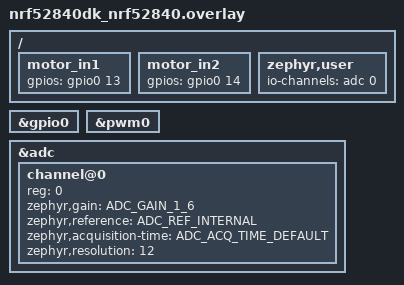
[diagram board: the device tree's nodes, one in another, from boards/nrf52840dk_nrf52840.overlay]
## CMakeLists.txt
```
# BLE Switch: Zephyr application (pure C application logic)
cmake_minimum_required(VERSION 3.20.0)
find_package(Zephyr REQUIRED HINTS $ENV{ZEPHYR_BASE})
project(ble_switch)

# Application sources (C)
target_sources(app PRIVATE
  src/main.c
  src/ble/ble_service.c
  src/motor/motor_driver.c
  src/motor/motor_fsm.c
  src/UI/button.c
  src/UI/led.c
  src/power/battery.c
  src/power/sleep.c
  src/storage/nvs_storage.c
)
target_include_directories(app PRIVATE
  ${CMAKE_CURRENT_SOURCE_DIR}/src
  ${CMAKE_CURRENT_SOURCE_DIR}/src/ble
  ${CMAKE_CURRENT_SOURCE_DIR}/src/motor
  ${CMAKE_CURRENT_SOURCE_DIR}/src/power
  ${CMAKE_CURRENT_SOURCE_DIR}/src/UI
  ${CMAKE_CURRENT_SOURCE_DIR}/src/storage
  ${CMAKE_CURRENT_SOURCE_DIR}/include
)
```

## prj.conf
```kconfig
# BLE Switch: BLE peripheral + GPIO/PWM (nRF5340 DK app core + net core HCI RPMsg)
CONFIG_BT=y
CONFIG_BT_PERIPHERAL=y
CONFIG_BT_DEVICE_NAME="BLE Switch"
CONFIG_BT_MAX_CONN=1
CONFIG_BT_MAX_PAIRED=1
CONFIG_BT_SMP=y
CONFIG_BT_APP_PASSKEY=y
CONFIG_BT_SETTINGS=y
CONFIG_SETTINGS=y

# Match Host ACL TX buffers to Controller's ACL packets
CONFIG_BT_BUF_ACL_TX_COUNT=7

CONFIG_GPIO=y
CONFIG_PWM=y
CONFIG_ADC=y
CONFIG_FLASH=y
CONFIG_FLASH_MAP=y
CONFIG_NVS=y

CONFIG_MAIN_STACK_SIZE=2048
CONFIG_SYSTEM_WORKQUEUE_STACK_SIZE=2048

CONFIG_LOG=y
CONFIG_LOG_DEFAULT_LEVEL=3
```

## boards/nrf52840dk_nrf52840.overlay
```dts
/*
 * nRF52840 DK overlay
 *
 * Enable GPIO/PWM and define simple GPIO-based motor control pins.
 * The actual H-bridge / driver hardware should connect to these pins.
 */

&gpio0 {
	status = "okay";
};

/*
 * Two GPIOs used for motor direction:
 * - motor_in1: drives \"ON\" direction
 * - motor_in2: drives \"OFF\" direction
 *
 * These can be wired to an H-bridge or driver inputs.
 */
/ {
	motor_in1: motor_in1 {
		gpios = <&gpio0 13 GPIO_ACTIVE_HIGH>;
	};

	motor_in2: motor_in2 {
		gpios = <&gpio0 14 GPIO_ACTIVE_HIGH>;
	};
};

&pwm0 {
	status = "okay";
};

/* ADC configuration for battery measurement.
 * We re-use the pattern from Zephyr's adc_dt sample and expose one
 * ADC channel via zephyr,user io-channels. For nRF52840 DK this maps
 * to AIN0 (P0.03) by default.
 */
/ {
	zephyr,user {
		io-channels = <&adc 0>;
	};
};

&adc {
	#address-cells = <1>;
	#size-cells = <0>;

	channel@0 {
		reg = <0>;
		zephyr,gain = "ADC_GAIN_1_6";
		zephyr,reference = "ADC_REF_INTERNAL";
		zephyr,acquisition-time = <ADC_ACQ_TIME_DEFAULT>;
		/* input-positive left as board default for AIN0 (P0.03) */
		zephyr,resolution = <12>;
	};
};
```

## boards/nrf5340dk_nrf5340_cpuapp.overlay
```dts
/*
 * nRF5340 DK (application core) overlay
 *
 * Enable GPIO/ADC and define simple GPIO-based motor control pins.
 * The actual H-bridge / driver hardware should connect to these pins.
 */

&gpio0 {
	status = "okay";
};

/*
 * Two GPIOs used for motor direction:
 * - motor_in1: drives "ON" direction
 * - motor_in2: drives "OFF" direction
 *
 * These can be wired to an H-bridge or driver inputs.
 */
/ {
	motor_in1: motor_in1 {
		gpios = <&gpio0 13 GPIO_ACTIVE_HIGH>;
	};

	motor_in2: motor_in2 {
		gpios = <&gpio0 14 GPIO_ACTIVE_HIGH>;
	};
};

/* ADC configuration for battery measurement.
 * We expose one ADC channel via zephyr,user io-channels; the exact analog pin
 * is defined by the board's ADC channel 0 default.
 */
/ {
	zephyr,user {
		io-channels = <&adc 0>;
	};
};

&adc {
	#address-cells = <1>;
	#size-cells = <0>;

	channel@0 {
		reg = <0>;
		zephyr,gain = "ADC_GAIN_1_6";
		zephyr,reference = "ADC_REF_INTERNAL";
		zephyr,acquisition-time = <ADC_ACQ_TIME_DEFAULT>;
		zephyr,resolution = <12>;
	};
};
```

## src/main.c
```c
/*
 * BLE Switch - main entry
 * Initializes app logic, BLE, button, storage trigger; then idle.
 */
#include "ble_service.h"
#include "button.h"
#include "nvs_storage.h"
#include "led.h"
#include <zephyr/init.h>
#include <zephyr/kernel.h>

extern void app_init(void);

static int ble_switch_init(void)
{
	app_init();
	return 0;
}

SYS_INIT(ble_switch_init, APPLICATION, CONFIG_APPLICATION_INIT_PRIORITY);

int main(void)
{
	led_init();
	ble_svc_init();
	button_init();
	nvs_storage_save_trigger_init();
	k_sleep(K_FOREVER);

	return 0;
}
```

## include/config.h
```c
#ifndef CONFIG_H
#define CONFIG_H

/* Global configuration parameters for the BLE switch application.
 * This is a placeholder and can be extended with user-tunable settings.
 */

#endif /* CONFIG_H */
```

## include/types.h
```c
#ifndef TYPES_H
#define TYPES_H

/* Common type definitions placeholder. The project currently uses only
 * standard integer types from <stdint.h>.
 */

#endif /* TYPES_H */
```

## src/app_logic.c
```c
#include <stdbool.h>
#include <stdint.h>
#include <zephyr/kernel.h>
#include <zephyr/logging/log.h>

LOG_MODULE_REGISTER(app_logic, LOG_LEVEL_INF);

#include "hw_glue.h"
#include "timer_glue.h"

/* Application state and logic previously implemented in Rust,
 * now reimplemented in pure C.
 */

typedef enum {
	STATE_IDLE = 0,
	STATE_MOVING_TO_ON = 1,
	STATE_MOVING_TO_OFF = 2,
	STATE_ERROR = 3,
} machine_state_t;

struct app_state {
	machine_state_t machine_state;
	uint8_t physical_state; /* 0 = off position, 1 = on position */
	uint8_t orientation;    /* 0 = normal, 1 = inverted */
	bool pairing_mode;
};

static struct app_state g_state;

static uint8_t app_get_battery_level(void)
{
	return battery_read_percent();
}

static bool app_is_battery_too_low_for_motion(void)
{
	return app_get_battery_level() <= 10;
}

static uint8_t app_get_logical_state(void)
{
	uint8_t p = g_state.physical_state & 1U;
	uint8_t o = g_state.orientation & 1U;
	if (o == 0U) {
		return p;
	}
	return (uint8_t)(1U - p);
}

static void app_request_on(void);
static void app_request_off(void);

static void app_request_toggle(void)
{
	uint8_t logical = app_get_logical_state();
	if (logical != 0U) {
		app_request_off();
	} else {
		app_request_on();
	}
}

#define MOTION_TIMEOUT_MS 1500U

static void app_request_on(void)
{
	if (g_state.machine_state != STATE_IDLE) {
		LOG_DBG("request_on ignored, state=%d", g_state.machine_state);
		return;
	}
	if (app_is_battery_too_low_for_motion()) {
		LOG_WRN("Battery too low, cannot move to ON (level=%u%%)", app_get_battery_level());
		g_state.machine_state = STATE_ERROR;
		led_flash_error();
		return;
	}
	LOG_INF("Moving to ON (orientation=%u, physical=%u)", g_state.orientation, g_state.physical_state);
	g_state.machine_state = STATE_MOVING_TO_ON;
	motor_power_enable(true);
	motor_move_to_on();
	timer_glue_start_motion_timeout_ms(MOTION_TIMEOUT_MS);
}

static void app_request_off(void)
{
	if (g_state.machine_state != STATE_IDLE) {
		LOG_DBG("request_off ignored, state=%d", g_state.machine_state);
		return;
	}
	if (app_is_battery_too_low_for_motion()) {
		LOG_WRN("Battery too low, cannot move to OFF (level=%u%%)", app_get_battery_level());
		g_state.machine_state = STATE_ERROR;
		led_flash_error();
		return;
	}
	LOG_INF("Moving to OFF (orientation=%u, physical=%u)", g_state.orientation, g_state.physical_state);
	g_state.machine_state = STATE_MOVING_TO_OFF;
	motor_power_enable(true);
	motor_move_to_off();
	timer_glue_start_motion_timeout_ms(MOTION_TIMEOUT_MS);
}

/* -------- Public API: application logic entry points -------- */

/* Called from SYS_INIT hook in main.c. */
void app_init(void)
{
	uint8_t v;

	g_state.machine_state = STATE_IDLE;
	g_state.physical_state = 0U;
	g_state.orientation = 0U;
	g_state.pairing_mode = false;

	if (storage_read_physical(&v) == 0) {
		g_state.physical_state = v & 1U;
	}
	if (storage_read_orientation(&v) == 0) {
		g_state.orientation = v & 1U;
	}
	LOG_INF("App init: physical=%u, orientation=%u", g_state.physical_state, g_state.orientation);
}

void app_handle_switch_control(uint8_t value)
{
	LOG_INF("Switch control write: value=%u (0=off,1=on,2=toggle)", value);
	switch (value) {
	case 0: /* logical off */
		if (g_state.orientation == 0U) {
			app_request_off();
		} else {
			app_request_on();
		}
		break;
	case 1: /* logical on */
		if (g_state.orientation == 0U) {
			app_request_on();
		} else {
			app_request_off();
		}
		break;
	case 2: /* toggle */
		app_request_toggle();
		break;
	default:
		break;
	}
}

uint8_t app_get_switch_state(void)
{
	uint8_t logical = app_get_logical_state();
	LOG_DBG("Get switch state: logical=%u (physical=%u, orientation=%u)",
		logical, g_state.physical_state, g_state.orientation);
	return app_get_logical_state();
}

uint8_t app_get_orientation(void)
{
	return g_state.orientation & 1U;
}

void app_set_orientation(uint8_t value)
{
	uint8_t v = value & 1U;
	g_state.orientation = v;
	(void)storage_write_orientation(v);
	LOG_INF("Set orientation: %u", v);
}

uint8_t app_get_battery_level_api(void)
{
	uint8_t lvl = app_get_battery_level();
	LOG_DBG("Battery level: %u%%", lvl);
	return lvl;
}

uint8_t app_get_error_state(void)
{
	return (uint8_t)g_state.machine_state;
}

void app_on_button_short(void)
{
	LOG_INF("Button short press -> toggle");
	app_request_toggle();
}

void app_on_button_long(void)
{
	g_state.pairing_mode = true;
	LOG_INF("Button long press -> pairing/factory reset");
	led_flash_pairing();
	hw_factory_reset();
}

void app_on_motion_complete(void)
{
	LOG_INF("Motion complete, state before=%d", g_state.machine_state);
	timer_glue_stop_motion_timeout();
	motor_stop();
	motor_power_enable(false);

	switch (g_state.machine_state) {
	case STATE_MOVING_TO_ON:
		g_state.physical_state = 1U;
		led_flash_feedback();
		LOG_INF("Reached ON position, physical_state=%u", g_state.physical_state);
		break;
	case STATE_MOVING_TO_OFF:
		g_state.physical_state = 0U;
		led_flash_feedback();
		LOG_INF("Reached OFF position, physical_state=%u", g_state.physical_state);
		break;
	default:
		break;
	}

	g_state.machine_state = STATE_IDLE;
}

void app_clear_error(void)
{
	LOG_INF("Clear error, state from=%d to IDLE", g_state.machine_state);
	g_state.machine_state = STATE_IDLE;
}

/* Called from save-state GPIO work handler in hw_glue.c. */
void app_save_physical_state_to_nvs(void)
{
	uint8_t v = g_state.physical_state & 1U;
	int rc = storage_write_physical(v);
	if (rc == 0) {
		LOG_INF("Saved physical_state=%u to NVS", v);
	} else {
		LOG_WRN("Failed to save physical_state=%u to NVS, rc=%d", v, rc);
	}
}
```

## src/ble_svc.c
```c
/*
 * BLE GATT: Remote Mechanical Switch Service
 * - Switch Control: read/write, 1 byte 0=off, 1=on, 2=toggle
 */
#include "ble_svc.h"
#include <zephyr/kernel.h>
#include <zephyr/logging/log.h>
#include <zephyr/bluetooth/bluetooth.h>
#include <zephyr/bluetooth/conn.h>
#include <zephyr/bluetooth/gatt.h>
#include <zephyr/bluetooth/uuid.h>
#include <zephyr/settings/settings.h>
#include <zephyr/bluetooth/services/bas.h>

LOG_MODULE_REGISTER(ble_svc, LOG_LEVEL_INF);

/* Application logic API */
extern uint8_t app_get_switch_state(void);
extern void app_handle_switch_control(uint8_t value);
extern uint8_t app_get_orientation(void);
extern void app_set_orientation(uint8_t value);
extern uint8_t app_get_battery_level_api(void);
extern uint8_t app_get_error_state(void);

/* Remote Mechanical Switch Service: 0x0001-... (custom 128-bit) */
#define BT_UUID_REMOTE_SWITCH_SVC_VAL \
	BT_UUID_128_ENCODE(0x00010000, 0x1234, 0x5678, 0x1234, 0x56789abcdef0)
/* Switch Control characteristic */
#define BT_UUID_SWITCH_CTRL_VAL \
	BT_UUID_128_ENCODE(0x00010000, 0x1234, 0x5678, 0x1234, 0x56789abcdef1)
/* Installation orientation: 0 = normal, 1 = inverted (read/write, persisted in NVS) */
#define BT_UUID_ORIENTATION_VAL \
	BT_UUID_128_ENCODE(0x00010000, 0x1234, 0x5678, 0x1234, 0x56789abcdef2)

static const struct bt_uuid_128 remote_switch_svc_uuid = BT_UUID_INIT_128(
	BT_UUID_REMOTE_SWITCH_SVC_VAL);
static const struct bt_uuid_128 switch_ctrl_uuid = BT_UUID_INIT_128(
	BT_UUID_SWITCH_CTRL_VAL);
static const struct bt_uuid_128 orientation_uuid = BT_UUID_INIT_128(
	BT_UUID_ORIENTATION_VAL);

/* Battery Level Service (BAS), 0x180F, with a single read-only Battery Level characteristic. */
static ssize_t read_batt_level(struct bt_conn *conn,
			       const struct bt_gatt_attr *attr,
			       void *buf, uint16_t len, uint16_t offset)
{
	uint8_t lvl = app_get_battery_level_api();
	return bt_gatt_attr_read(conn, attr, buf, len, offset, &lvl, sizeof(lvl));
}

BT_GATT_SERVICE_DEFINE(bas_svc,
	BT_GATT_PRIMARY_SERVICE(BT_UUID_BAS),
	BT_GATT_CHARACTERISTIC(BT_UUID_BAS_BATTERY_LEVEL,
			       BT_GATT_CHRC_READ,
			       BT_GATT_PERM_READ,
			       read_batt_level, NULL, NULL),
);

/* Application-provided fixed passkey.
 * For now this is hard-coded; in future it can be loaded from NVS or provided by MCUboot.
 */
#if defined(CONFIG_BT_APP_PASSKEY)
static uint32_t app_fixed_passkey = 123456;

static uint32_t auth_app_passkey(struct bt_conn *conn)
{
	ARG_UNUSED(conn);
	return app_fixed_passkey;
}

static const struct bt_conn_auth_cb auth_cb = {
	.app_passkey = auth_app_passkey,
};
#endif

/* Simple error/status characteristic: exposes the current state/error code from Rust.
 * 0 = Idle/OK, 1 = MovingToOn, 2 = MovingToOff, 3 = Error.
 */
static ssize_t read_error_state(struct bt_conn *conn,
				const struct bt_gatt_attr *attr,
				void *buf, uint16_t len, uint16_t offset)
{
	uint8_t val = app_get_error_state();
	return bt_gatt_attr_read(conn, attr, buf, len, offset, &val, sizeof(val));
}

BT_GATT_SERVICE_DEFINE(status_svc,
	BT_GATT_PRIMARY_SERVICE(BT_UUID_DECLARE_16(0x180A)), /* reuse Device Info UUID namespace */
	BT_GATT_CHARACTERISTIC(BT_UUID_DECLARE_16(0x2A3D), /* arbitrary 16-bit for status */
			       BT_GATT_CHRC_READ,
			       BT_GATT_PERM_READ,
			       read_error_state, NULL, NULL),
);

static ssize_t read_switch_ctrl(struct bt_conn *conn,
				const struct bt_gatt_attr *attr,
				void *buf, uint16_t len, uint16_t offset)
{
	uint8_t val = app_get_switch_state();
	return bt_gatt_attr_read(conn, attr, buf, len, offset, &val, sizeof(val));
}

static ssize_t write_switch_ctrl(struct bt_conn *conn,
				 const struct bt_gatt_attr *attr,
				 const void *buf, uint16_t len, uint16_t offset,
				 uint8_t flags)
{
	if (offset != 0 || len != 1) {
		return BT_GATT_ERR(BT_ATT_ERR_INVALID_OFFSET);
	}

	uint8_t val = *(const uint8_t *)buf;
	switch (val) {
		case 0:
		case 1:
		case 2:
			break;
		default:
			return BT_GATT_ERR(BT_ATT_ERR_VALUE_NOT_ALLOWED);
	}

	app_handle_switch_control(val);
	return len;
}

static ssize_t read_orientation(struct bt_conn *conn,
				const struct bt_gatt_attr *attr,
				void *buf, uint16_t len, uint16_t offset)
{
	uint8_t val = app_get_orientation();
	LOG_DBG("GATT Orientation read: %u", val);
	return bt_gatt_attr_read(conn, attr, buf, len, offset, &val, sizeof(val));
}

static ssize_t write_orientation(struct bt_conn *conn,
				  const struct bt_gatt_attr *attr,
				  const void *buf, uint16_t len, uint16_t offset,
				  uint8_t flags)
{
	if (offset != 0 || len != 1) {
		return BT_GATT_ERR(BT_ATT_ERR_INVALID_OFFSET);
	}

	uint8_t val = *(const uint8_t *)buf;
	switch (val) {
	case 0:
	case 1:
		break;
	default:
		return BT_GATT_ERR(BT_ATT_ERR_VALUE_NOT_ALLOWED);
	}

	LOG_INF("GATT Orientation write: %u", val);
	app_set_orientation(val);
	return len;
}

BT_GATT_SERVICE_DEFINE(remote_switch_svc,
	BT_GATT_PRIMARY_SERVICE(&remote_switch_svc_uuid),
	BT_GATT_CHARACTERISTIC(&switch_ctrl_uuid.uuid,
			       BT_GATT_CHRC_READ | BT_GATT_CHRC_WRITE,
			       BT_GATT_PERM_READ | BT_GATT_PERM_WRITE,
			       read_switch_ctrl, write_switch_ctrl, NULL),
	BT_GATT_CHARACTERISTIC(&orientation_uuid.uuid,
			       BT_GATT_CHRC_READ | BT_GATT_CHRC_WRITE,
			       BT_GATT_PERM_READ | BT_GATT_PERM_WRITE,
			       read_orientation, write_orientation, NULL),
);

static const struct bt_data ad[] = {
	BT_DATA_BYTES(BT_DATA_FLAGS, (BT_LE_AD_GENERAL | BT_LE_AD_NO_BREDR)),
	BT_DATA_BYTES(BT_DATA_UUID128_ALL, BT_UUID_REMOTE_SWITCH_SVC_VAL),
	/* Advertise standard Battery Service (0x180F) as 16-bit UUID */
	BT_DATA_BYTES(BT_DATA_UUID16_ALL, 0x0F, 0x18),
};

static const struct bt_data sd[] = {
	BT_DATA(BT_DATA_NAME_COMPLETE, CONFIG_BT_DEVICE_NAME,
		sizeof(CONFIG_BT_DEVICE_NAME) - 1),
};

static void bt_ready(int err)
{
	if (err) {
		LOG_ERR("bt_enable failed: %d", err);
		return;
	}

	if (IS_ENABLED(CONFIG_SETTINGS)) {
        settings_load();
    }

	LOG_INF("bt_enable OK, starting advertising");
	err = ble_svc_advertise_start();
	if (err) {
		LOG_ERR("Advertising start failed: %d", err);
	} else {
		LOG_INF("Advertising started successfully");
	}
}

void ble_svc_init(void)
{
	int err;

#if defined(CONFIG_BT_APP_PASSKEY)
	bt_conn_auth_cb_register(&auth_cb);
#endif

	err = bt_enable(bt_ready);
	if (err) {
		LOG_ERR("bt_enable failed: %d", err);
	}
}

int ble_svc_advertise_start(void)
{
	/* Use GAP recommended fast connectable advertising parameters */
	return bt_le_adv_start(BT_LE_ADV_CONN_FAST_1, ad, ARRAY_SIZE(ad),
			       sd, ARRAY_SIZE(sd));
}
```

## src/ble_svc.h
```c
#ifndef BLE_SVC_H
#define BLE_SVC_H

/* Initialize BLE stack and register GATT service. Call once after bt_enable. */
void ble_svc_init(void);

/* Start advertising. Call from bt_ready callback. */
int ble_svc_advertise_start(void);

#endif
```

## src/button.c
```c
#include "button.h"
#include <zephyr/kernel.h>
#include <zephyr/device.h>
#include <zephyr/drivers/gpio.h>
#include <zephyr/devicetree.h>
#include <zephyr/logging/log.h>

LOG_MODULE_REGISTER(button, LOG_LEVEL_INF);

extern void app_on_button_short(void);
extern void app_on_button_long(void);

#define LONG_PRESS_MS 2000
#define BUTTON_PRESSED_VAL 1

#if DT_NODE_EXISTS(DT_ALIAS(sw0))
#define SW0_NODE DT_ALIAS(sw0)
#else
#error "No sw0 alias (button) in devicetree"
#endif

static const struct gpio_dt_spec button = GPIO_DT_SPEC_GET(SW0_NODE, gpios);
static struct gpio_callback button_cb;
static struct k_timer long_press_timer;
static volatile bool long_press_fired;

static void long_press_expiry(struct k_timer *timer)
{
	ARG_UNUSED(timer);
	long_press_fired = true;
	LOG_INF("Button long-press timeout");
	app_on_button_long();
}

static void button_handler(const struct device *dev, struct gpio_callback *cb, uint32_t pins)
{
	ARG_UNUSED(dev);
	ARG_UNUSED(cb);
	ARG_UNUSED(pins);

	int val = gpio_pin_get_dt(&button);
	if (val == BUTTON_PRESSED_VAL) {
		/* Pressed: start long-press timer */
		LOG_DBG("Button pressed");
		long_press_fired = false;
		k_timer_start(&long_press_timer, K_MSEC(LONG_PRESS_MS), K_NO_WAIT);
	} else {
		/* Released */
		LOG_DBG("Button released");
		k_timer_stop(&long_press_timer);
		if (!long_press_fired) {
			LOG_INF("Button short press");
			app_on_button_short();
		}
	}
}

void button_init(void)
{
	if (!gpio_is_ready_dt(&button)) {
		return;
	}
	gpio_pin_configure_dt(&button, GPIO_INPUT);
	gpio_pin_interrupt_configure_dt(&button, GPIO_INT_EDGE_BOTH);
	k_timer_init(&long_press_timer, long_press_expiry, NULL);
	gpio_init_callback(&button_cb, button_handler, BIT(button.pin));
	gpio_add_callback(button.port, &button_cb);
}
```

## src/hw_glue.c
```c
#include "hw_glue.h"
#include <stdbool.h>
#include <zephyr/kernel.h>
#include <zephyr/device.h>
#include <zephyr/drivers/gpio.h>
#include <zephyr/devicetree.h>
#include <zephyr/storage/flash_map.h>
#include <zephyr/fs/nvs.h>
#include <zephyr/drivers/adc.h>
#include <zephyr/bluetooth/bluetooth.h>
#include <zephyr/logging/log.h>

LOG_MODULE_REGISTER(hw_glue, LOG_LEVEL_INF);

/* Motor: simple GPIO-based H-bridge style control using GPIO0 pins.
 * Two pins (IN1/IN2) drive ON/OFF direction.
 */

#define MOTOR_IN1_PIN 13
#define MOTOR_IN2_PIN 14

static const struct device *motor_port = DEVICE_DT_GET(DT_NODELABEL(gpio0));
static bool motor_pins_inited;

static void motor_init_pins(void)
{
	if (motor_pins_inited) {
		return;
	}
	if (!device_is_ready(motor_port)) {
		return;
	}
	gpio_pin_configure(motor_port, MOTOR_IN1_PIN, GPIO_OUTPUT_INACTIVE);
	gpio_pin_configure(motor_port, MOTOR_IN2_PIN, GPIO_OUTPUT_INACTIVE);
	motor_pins_inited = true;
}

void motor_move_to_on(void)
{
	motor_init_pins();
	if (!motor_pins_inited) {
		return;
	}
	/* Drive ON direction: IN1=1, IN2=0 */
	LOG_INF("Motor move_to_on");
	gpio_pin_set(motor_port, MOTOR_IN1_PIN, 1);
	gpio_pin_set(motor_port, MOTOR_IN2_PIN, 0);
}

void motor_move_to_off(void)
{
	motor_init_pins();
	if (!motor_pins_inited) {
		return;
	}
	/* Drive OFF direction: IN1=0, IN2=1 */
	LOG_INF("Motor move_to_off");
	gpio_pin_set(motor_port, MOTOR_IN1_PIN, 0);
	gpio_pin_set(motor_port, MOTOR_IN2_PIN, 1);
}

void motor_stop(void)
{
	motor_init_pins();
	if (!motor_pins_inited) {
		return;
	}
	/* Brake / stop: both low */
	LOG_DBG("Motor stop");
	gpio_pin_set(motor_port, MOTOR_IN1_PIN, 0);
	gpio_pin_set(motor_port, MOTOR_IN2_PIN, 0);
}

void motor_power_enable(bool enable)
{
	/* For simple two-pin control, power enable just maps to stop/idle. */
	if (!enable) {
		motor_stop();
	}
}

/* LED: short flash if led0 exists (e.g. nRF5340 DK LED1) */
#if DT_NODE_EXISTS(DT_ALIAS(led0))
static const struct gpio_dt_spec led = GPIO_DT_SPEC_GET(DT_ALIAS(led0), gpios);
static struct k_timer led_off_timer;
static bool led_timer_init_done;
static void led_off_handler(struct k_timer *t)
{
	ARG_UNUSED(t);
	gpio_pin_set_dt(&led, 0);
}
static void led_flash_ms(uint32_t ms)
{
	if (!gpio_is_ready_dt(&led)) return;
	if (!led_timer_init_done) {
		k_timer_init(&led_off_timer, led_off_handler, NULL);
		led_timer_init_done = true;
	}
	gpio_pin_configure_dt(&led, GPIO_OUTPUT_INACTIVE);
	gpio_pin_set_dt(&led, 1);
	k_timer_start(&led_off_timer, K_MSEC(ms), K_NO_WAIT);
}
#else
static void led_flash_ms(uint32_t ms) { (void)ms; }
#endif

void led_flash_pairing(void)
{
	LOG_INF("LED pairing flash");
	led_flash_ms(100);
}

void led_flash_feedback(void) { led_flash_ms(80); }
void led_flash_error(void) { led_flash_ms(200); }

/* Simple NVS-backed storage for logical switch state.
 * Uses the fixed-partition labeled 'storage' (node label storage_partition).
 */
static struct nvs_fs nvs;
static bool nvs_inited;

static int storage_nvs_init(void)
{
	int rc;
	const struct flash_area *fa;

	if (nvs_inited) {
		return 0;
	}

	rc = flash_area_open(FIXED_PARTITION_ID(storage_partition), &fa);
	if (rc) {
		return rc;
	}

	nvs.offset = fa->fa_off;
	nvs.sector_size = fa->fa_size / 2;
	nvs.sector_count = 2;
	nvs.flash_device = fa->fa_dev;

	rc = nvs_mount(&nvs);
	if (rc) {
		return rc;
	}

	nvs_inited = true;
	return 0;
}

/* NVS: physical motor position (0/1) and logical↔physical mapping (0=normal, 1=inverted).
 * Physical state is written only when save-state GPIO goes low (to limit NVS wear). */
#define NVS_ID_PHYSICAL_STATE 1
#define NVS_ID_ORIENTATION    2

int storage_read_physical(uint8_t *out_value)
{
	int rc;
	uint8_t val;

	rc = storage_nvs_init();
	if (rc) {
		if (out_value) *out_value = 0;
		return rc;
	}
	rc = nvs_read(&nvs, NVS_ID_PHYSICAL_STATE, &val, sizeof(val));
	if (rc < 0) {
		if (out_value) *out_value = 0;
		return rc;
	}
	if (out_value) *out_value = val & 1;
	return 0;
}

int storage_write_physical(uint8_t value)
{
	int rc = storage_nvs_init();
	if (rc) return rc;
	value &= 1;
	rc = nvs_write(&nvs, NVS_ID_PHYSICAL_STATE, &value, sizeof(value)) < 0 ? -1 : 0;
	if (rc == 0) {
		LOG_INF("NVS write physical_state=%u", value);
	} else {
		LOG_WRN("NVS write physical_state failed, rc=%d", rc);
	}
	return rc;
}

int storage_read_orientation(uint8_t *out_value)
{
	int rc;
	uint8_t val;

	rc = storage_nvs_init();
	if (rc) {
		if (out_value) {
			*out_value = 0;
		}
		return rc;
	}

	rc = nvs_read(&nvs, NVS_ID_ORIENTATION, &val, sizeof(val));
	if (rc < 0) {
		if (out_value) {
			*out_value = 0;
		}
		return rc;
	}

	if (out_value) {
		*out_value = val & 1;
	}
	return 0;
}

int storage_write_orientation(uint8_t value)
{
	int rc = storage_nvs_init();
	if (rc) {
		return rc;
	}
	value &= 1;
	rc = nvs_write(&nvs, NVS_ID_ORIENTATION, &value, sizeof(value)) < 0 ? -1 : 0;
	if (rc == 0) {
		LOG_INF("NVS write orientation=%u", value);
	} else {
		LOG_WRN("NVS write orientation failed, rc=%d", rc);
	}
	return rc;
}

/* Factory reset: clear NVS state and all BLE bonds. */
void hw_factory_reset(void)
{
	int rc = storage_nvs_init();
	if (rc == 0) {
		(void)nvs_delete(&nvs, NVS_ID_PHYSICAL_STATE);
		(void)nvs_delete(&nvs, NVS_ID_ORIENTATION);
	}
	LOG_INF("Factory reset: cleared NVS and BLE bonds");
	(void)bt_unpair(BT_ID_DEFAULT, NULL);
}

/* Save-state trigger: when this GPIO goes low, current physical state is written to NVS (via work, to limit wear). */
#define SAVE_STATE_TRIGGER_PIN 15

extern void app_save_physical_state_to_nvs(void);

static struct k_work save_state_work;
static void save_state_work_handler(struct k_work *w)
{
	ARG_UNUSED(w);
	app_save_physical_state_to_nvs();
}

static void save_state_gpio_callback(const struct device *port, struct gpio_callback *cb, gpio_port_pins_t pins)
{
	ARG_UNUSED(port);
	ARG_UNUSED(cb);
	ARG_UNUSED(pins);
	LOG_INF("Save-state GPIO falling edge");
	k_work_submit(&save_state_work);
}

static struct gpio_callback save_state_cb;
static bool save_state_trigger_inited;

void hw_save_state_trigger_init(void)
{
	const struct device *gpio0 = DEVICE_DT_GET(DT_NODELABEL(gpio0));
	if (!device_is_ready(gpio0) || save_state_trigger_inited) {
		return;
	}
	k_work_init(&save_state_work, save_state_work_handler);
	int ret = gpio_pin_configure(gpio0, SAVE_STATE_TRIGGER_PIN,
				     GPIO_INPUT | GPIO_PULL_UP);
	if (ret) {
		return;
	}
	gpio_init_callback(&save_state_cb, save_state_gpio_callback,
			   BIT(SAVE_STATE_TRIGGER_PIN));
	ret = gpio_add_callback(gpio0, &save_state_cb);
	if (ret) {
		return;
	}
	ret = gpio_pin_interrupt_configure(gpio0, SAVE_STATE_TRIGGER_PIN,
					   GPIO_INT_EDGE_FALLING);
	if (ret) {
		return;
	}
	save_state_trigger_inited = true;
	LOG_INF("Save-state trigger initialized on P0.%d", SAVE_STATE_TRIGGER_PIN);
}

/* Battery measurement via ADC using zephyr,user io-channels[0]. */

#if DT_NODE_EXISTS(DT_PATH(zephyr_user)) && DT_NODE_HAS_PROP(DT_PATH(zephyr_user), io_channels)
static const struct adc_dt_spec batt_adc_chan =
	ADC_DT_SPEC_GET_BY_IDX(DT_PATH(zephyr_user), 0);

static int battery_adc_init(void)
{
	int err;

	if (!adc_is_ready_dt(&batt_adc_chan)) {
		return -ENODEV;
	}

	err = adc_channel_setup_dt(&batt_adc_chan);
	if (err < 0) {
		return err;
	}

	return 0;
}

uint8_t battery_read_percent(void)
{
	int err;
	struct adc_sequence seq = {
		.buffer_size = sizeof(uint16_t),
	};
	uint16_t sample = 0;
	int32_t mv;

	err = battery_adc_init();
	if (err < 0) {
		return 100;
	}

	seq.buffer = &sample;
	adc_sequence_init_dt(&batt_adc_chan, &seq);

	err = adc_read_dt(&batt_adc_chan, &seq);
	if (err < 0) {
		return 100;
	}

	mv = sample;
	err = adc_raw_to_millivolts_dt(&batt_adc_chan, &mv);
	if (err < 0) {
		/* Fallback: treat raw as millivolts-ish. */
		mv = sample;
	}

	/* Simple linear mapping: 3.0V -> 0%, 4.2V -> 100% (typical Li-ion) */
	const int32_t min_mv = 3000;
	const int32_t max_mv = 4200;

	if (mv <= min_mv) {
		return 0;
	}
	if (mv >= max_mv) {
		return 100;
	}
	return (uint8_t)(((mv - min_mv) * 100) / (max_mv - min_mv));
}
#else
uint8_t battery_read_percent(void)
{
	/* No ADC config: report dummy 100%. */
	return 100;
}
#endif
```

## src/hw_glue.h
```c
#ifndef HW_GLUE_H
#define HW_GLUE_H

#include <stdbool.h>
#include <stdint.h>

/* Motor (PWM/servo) - called from Rust */
void motor_move_to_on(void);
void motor_move_to_off(void);
void motor_stop(void);

/* Motor power enable - called from Rust */
void motor_power_enable(bool enable);

/* LED feedback - called from Rust */
void led_flash_pairing(void);
void led_flash_feedback(void);
void led_flash_error(void);

/* Factory reset helper - called from Rust UI code */
void hw_factory_reset(void);

/* Storage (NVS) - called from Rust. Physical state written only on save-state GPIO low. */
int storage_read_physical(uint8_t *out_value);
int storage_write_physical(uint8_t value);
int storage_read_orientation(uint8_t *out_value);
int storage_write_orientation(uint8_t value);

/* Call from main to enable save-state trigger: when GPIO goes low, physical state is written to NVS. */
void hw_save_state_trigger_init(void);

/* Battery - called from Rust; returns 0..100 */
uint8_t battery_read_percent(void);

#endif
```

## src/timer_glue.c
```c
#include "timer_glue.h"
#include <zephyr/kernel.h>
#include <zephyr/logging/log.h>

LOG_MODULE_REGISTER(timer_glue, LOG_LEVEL_DBG);

extern void app_on_motion_complete(void);

static struct k_timer motion_timer;

static void motion_timeout_handler(struct k_timer *timer)
{
	ARG_UNUSED(timer);
	LOG_INF("Motion timeout fired");
	app_on_motion_complete();
}

void timer_glue_init(void)
{
	k_timer_init(&motion_timer, motion_timeout_handler, NULL);
	LOG_DBG("Motion timer initialized");
}

void timer_glue_start_motion_timeout_ms(uint32_t ms)
{
	LOG_DBG("Start motion timeout: %u ms", ms);
	k_timer_start(&motion_timer, K_MSEC(ms), K_FOREVER);
}

void timer_glue_stop_motion_timeout(void)
{
	LOG_DBG("Stop motion timeout");
	k_timer_stop(&motion_timer);
}
```

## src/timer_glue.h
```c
#ifndef TIMER_GLUE_H
#define TIMER_GLUE_H

#include <stdint.h>

void timer_glue_init(void);
void timer_glue_start_motion_timeout_ms(uint32_t ms);
void timer_glue_stop_motion_timeout(void);

#endif
```
